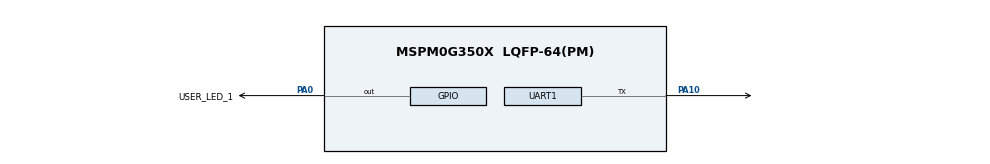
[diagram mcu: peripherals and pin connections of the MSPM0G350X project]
/**
 * @cliArgs --device "MSPM0G350X" --package "LQFP-64(PM)" --part "Default" --product "mspm0_sdk@1.20.01.06"
 * @versions {"tool":"1.18.0+3266"}
 */

/**
 * Import the modules used in this configuration.
 */
const ADC12  = scripting.addModule("/ti/driverlib/ADC12", {}, false);
const ADC121 = ADC12.addInstance();
const Board  = scripting.addModule("/ti/driverlib/Board");
const GPIO   = scripting.addModule("/ti/driverlib/GPIO", {}, false);
const GPIO1  = GPIO.addInstance();
const SYSCTL = scripting.addModule("/ti/driverlib/SYSCTL");
const UART   = scripting.addModule("/ti/driverlib/UART", {}, false);
const UART1  = UART.addInstance();

/**
 * Write custom configuration values to the imported modules.
 */
ADC121.$name                      = "ADC12_0";
ADC121.sampClkSrc                 = "DL_ADC12_CLOCK_ULPCLK";
ADC121.adcMem0chansel             = "DL_ADC12_INPUT_CHAN_2";
ADC121.sampleTime0                = "125 us";
ADC121.enabledInterrupts          = ["DL_ADC12_INTERRUPT_MEM0_RESULT_LOADED"];
ADC121.powerDownMode              = "DL_ADC12_POWER_DOWN_MODE_MANUAL";
ADC121.adcMem0avgen               = true;
ADC121.sampClkDiv                 = "DL_ADC12_CLOCK_DIVIDE_32";
ADC121.hwNumerator                = "DL_ADC12_HW_AVG_NUM_ACC_128";
ADC121.peripheral.$assign         = "ADC0";
ADC121.peripheral.adcPin2.$assign = "PA25";
ADC121.adcPin2Config.$name        = "ti_driverlib_gpio_GPIOPinGeneric0";


GPIO1.$name                         = "GPIO_LEDS";
GPIO1.port                          = "PORTA";
GPIO1.portSegment                   = "Lower";
GPIO1.associatedPins[0].$name       = "USER_LED_1";
GPIO1.associatedPins[0].assignedPin = "0";
GPIO1.associatedPins[0].pin.$assign = "PA0";

SYSCTL.forceDefaultClkConfig = true;

UART1.$name                    = "UART_0";
UART1.enableFIFO               = true;
UART1.rxFifoThreshold          = "DL_UART_RX_FIFO_LEVEL_ONE_ENTRY";
UART1.txFifoThreshold          = "DL_UART_TX_FIFO_LEVEL_3_4_EMPTY";
UART1.direction                = "TX";
UART1.peripheral.$assign       = "UART0";
UART1.peripheral.txPin.$assign = "PA10";
UART1.txPinConfig.$name        = "ti_driverlib_gpio_GPIOPinGeneric1";

/**
 * Pinmux solution for unlocked pins/peripherals. This ensures that minor changes to the automatic solver in a future
 * version of the tool will not impact the pinmux you originally saw.  These lines can be completely deleted in order to
 * re-solve from scratch.
 */
Board.peripheral.$suggestSolution          = "DEBUGSS";
Board.peripheral.swclkPin.$suggestSolution = "PA20";
Board.peripheral.swdioPin.$suggestSolution = "PA19";
SYSCTL.peripheral.$suggestSolution         = "SYSCTL";
